# MCU_R5FSS0_CORE0_ECC_AGGR_CORE0_ECC_AGGR register map
Vendor: Texas Instruments
Peripheral module from a debugger description file (folder J721S2).
Registers are 32-bit, access not given, reset 0x0 unless marked. A register's access mark holds for its fields unless they carry their own. Offsets are as the file gives them; lines under a group give offsets from that group; [hi:lo] are bit positions; {n}, {i} and the like mark numbered series; 'fields as' and 'values as' point back to an identical list; <NAME> marks a mode.

## MCU_R5FSS0_CORE0_ECC_AGGR_CORE0_ECC_AGGR
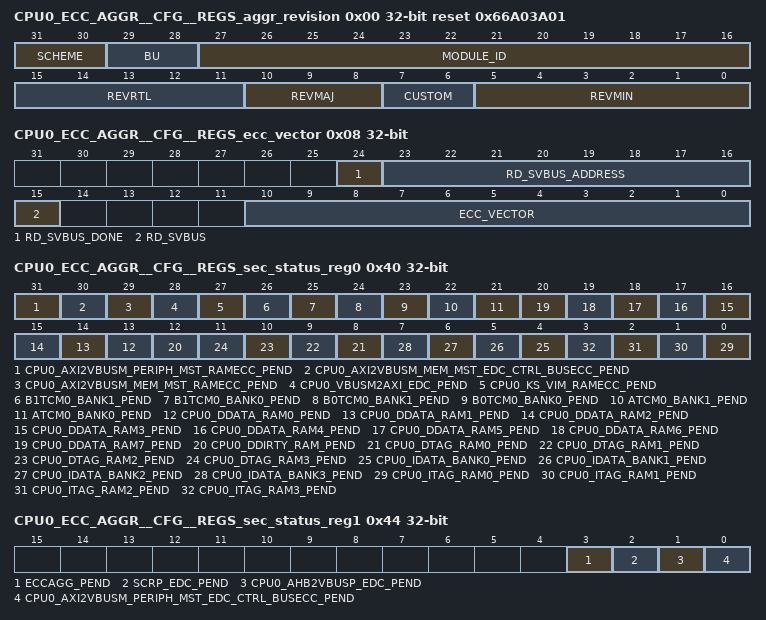
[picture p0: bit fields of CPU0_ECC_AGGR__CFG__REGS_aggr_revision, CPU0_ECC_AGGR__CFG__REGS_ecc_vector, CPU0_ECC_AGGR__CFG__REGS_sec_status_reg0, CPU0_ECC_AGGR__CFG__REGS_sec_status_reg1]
0x00 CPU0_ECC_AGGR__CFG__REGS_aggr_revision ro reset 0x66A03A01 — Revision parameters
  [31:30] SCHEME
  [29:28] BU
  [27:16] MODULE_ID
  [15:11] REVRTL — RTL version
  [10:8] REVMAJ — Major version
  [7:6] CUSTOM — Custom version
  [5:0] REVMIN — Minor version
0x08 CPU0_ECC_AGGR__CFG__REGS_ecc_vector — ECC Vector Register
  [24] RD_SVBUS_DONE — Status to indicate if read on serial VBUS is complete, write of any value will clear this bit. (access R/W1TC)
  [23:16] RD_SVBUS_ADDRESS rw — Read address
  [15] RD_SVBUS — Write 1 to trigger a read on the serial VBUS (access R/W1TS)
  [10:0] ECC_VECTOR rw — Value written to select the corresponding ECC RAM for control or status
0x0C CPU0_ECC_AGGR__CFG__REGS_misc_status ro reset 0x24 — Misc Status
  [10:0] NUM_RAMS — Indicates the number of RAMS serviced by the ECC aggregator
0x10 CPU0_ECC_AGGR__CFG__REGS_reserved_svbus rw — Reference other documents that contain the ECC RAM wrapper and EDC controller serial vbus register sets.
  [31:0] DATA — Serial VBUS register data
0x3C CPU0_ECC_AGGR__CFG__REGS_sec_eoi_reg — EOI Register
  [0] EOI_WR — EOI Register (access R/W1TS)
0x40 CPU0_ECC_AGGR__CFG__REGS_sec_status_reg0 — Interrupt Status Register 0
  [31] CPU0_AXI2VBUSM_PERIPH_MST_RAMECC_PEND — Interrupt Pending Status for cpu0_axi2vbusm_periph_mst_ramecc_pend (access R/W1TS)
  [30] CPU0_AXI2VBUSM_MEM_MST_EDC_CTRL_BUSECC_PEND — Interrupt Pending Status for cpu0_axi2vbusm_mem_mst_edc_ctrl_busecc_pend (access R/W1TS)
  [29] CPU0_AXI2VBUSM_MEM_MST_RAMECC_PEND — Interrupt Pending Status for cpu0_axi2vbusm_mem_mst_ramecc_pend (access R/W1TS)
  [28] CPU0_VBUSM2AXI_EDC_PEND — Interrupt Pending Status for cpu0_vbusm2axi_edc_pend (access R/W1TS)
  [27] CPU0_KS_VIM_RAMECC_PEND — Interrupt Pending Status for cpu0_ks_vim_ramecc_pend (access R/W1TS)
  [26] B1TCM0_BANK1_PEND — Interrupt Pending Status for b1tcm0_bank1_pend (access R/W1TS)
  [25] B1TCM0_BANK0_PEND — Interrupt Pending Status for b1tcm0_bank0_pend (access R/W1TS)
  [24] B0TCM0_BANK1_PEND — Interrupt Pending Status for b0tcm0_bank1_pend (access R/W1TS)
  [23] B0TCM0_BANK0_PEND — Interrupt Pending Status for b0tcm0_bank0_pend (access R/W1TS)
  [22] ATCM0_BANK1_PEND — Interrupt Pending Status for atcm0_bank1_pend (access R/W1TS)
  [21] ATCM0_BANK0_PEND — Interrupt Pending Status for atcm0_bank0_pend (access R/W1TS)
  [n+13] CPU0_DDATA_RAM{n}_PEND (n=0..7) — Interrupt Pending Status for cpu0_ddata_ram{n}_pend (access R/W1TS)
  [12] CPU0_DDIRTY_RAM_PEND — Interrupt Pending Status for cpu0_ddirty_ram_pend (access R/W1TS)
  [n+8] CPU0_DTAG_RAM{n}_PEND (n=0..3) — Interrupt Pending Status for cpu0_dtag_ram{n}_pend (access R/W1TS)
  [n+4] CPU0_IDATA_BANK{n}_PEND (n=0..3) — Interrupt Pending Status for cpu0_idata_bank{n}_pend (access R/W1TS)
  [n] CPU0_ITAG_RAM{n}_PEND (n=0..3) — Interrupt Pending Status for cpu0_itag_ram{n}_pend (access R/W1TS)
0x44 CPU0_ECC_AGGR__CFG__REGS_sec_status_reg1 — Interrupt Status Register 1
  [3] ECCAGG_PEND — Interrupt Pending Status for eccagg_pend (access R/W1TS)
  [2] SCRP_EDC_PEND — Interrupt Pending Status for scrp_edc_pend (access R/W1TS)
  [1] CPU0_AHB2VBUSP_EDC_PEND — Interrupt Pending Status for cpu0_ahb2vbusp_edc_pend (access R/W1TS)
  [0] CPU0_AXI2VBUSM_PERIPH_MST_EDC_CTRL_BUSECC_PEND — Interrupt Pending Status for cpu0_axi2vbusm_periph_mst_edc_ctrl_busecc_pend (access R/W1TS)
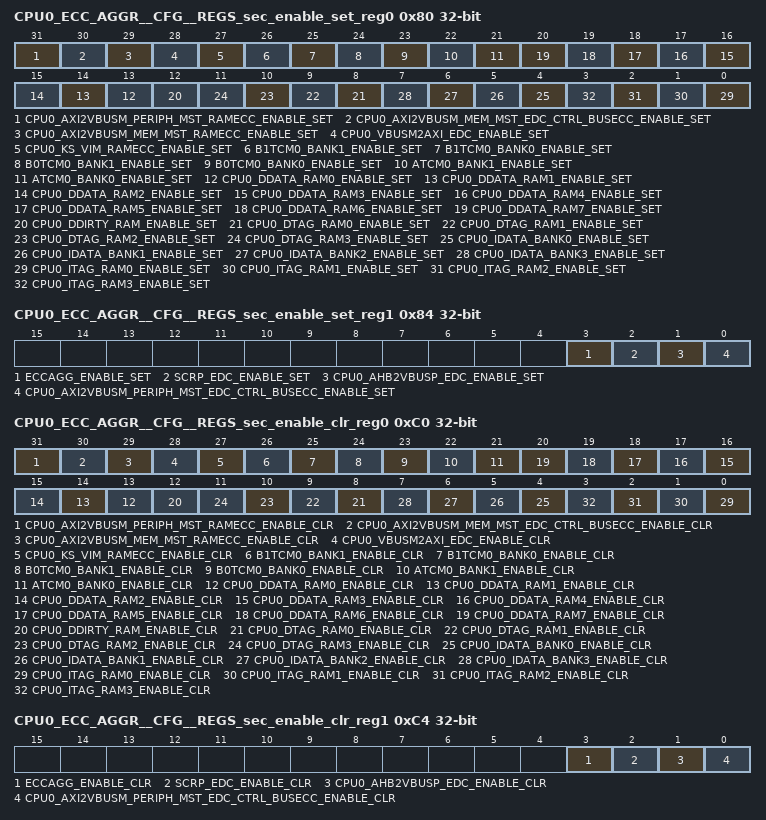
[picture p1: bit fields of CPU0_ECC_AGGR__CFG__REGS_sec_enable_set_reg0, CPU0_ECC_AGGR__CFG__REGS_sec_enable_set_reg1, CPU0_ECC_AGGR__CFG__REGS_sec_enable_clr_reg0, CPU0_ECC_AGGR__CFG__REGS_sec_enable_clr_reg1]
0x80 CPU0_ECC_AGGR__CFG__REGS_sec_enable_set_reg0 — Interrupt Enable Set Register 0
  [31] CPU0_AXI2VBUSM_PERIPH_MST_RAMECC_ENABLE_SET — Interrupt Enable Set Register for cpu0_axi2vbusm_periph_mst_ramecc_pend (access R/W1TS)
  [30] CPU0_AXI2VBUSM_MEM_MST_EDC_CTRL_BUSECC_ENABLE_SET — Interrupt Enable Set Register for cpu0_axi2vbusm_mem_mst_edc_ctrl_busecc_pend (access R/W1TS)
  [29] CPU0_AXI2VBUSM_MEM_MST_RAMECC_ENABLE_SET — Interrupt Enable Set Register for cpu0_axi2vbusm_mem_mst_ramecc_pend (access R/W1TS)
  [28] CPU0_VBUSM2AXI_EDC_ENABLE_SET — Interrupt Enable Set Register for cpu0_vbusm2axi_edc_pend (access R/W1TS)
  [27] CPU0_KS_VIM_RAMECC_ENABLE_SET — Interrupt Enable Set Register for cpu0_ks_vim_ramecc_pend (access R/W1TS)
  [26] B1TCM0_BANK1_ENABLE_SET — Interrupt Enable Set Register for b1tcm0_bank1_pend (access R/W1TS)
  [25] B1TCM0_BANK0_ENABLE_SET — Interrupt Enable Set Register for b1tcm0_bank0_pend (access R/W1TS)
  [24] B0TCM0_BANK1_ENABLE_SET — Interrupt Enable Set Register for b0tcm0_bank1_pend (access R/W1TS)
  [23] B0TCM0_BANK0_ENABLE_SET — Interrupt Enable Set Register for b0tcm0_bank0_pend (access R/W1TS)
  [22] ATCM0_BANK1_ENABLE_SET — Interrupt Enable Set Register for atcm0_bank1_pend (access R/W1TS)
  [21] ATCM0_BANK0_ENABLE_SET — Interrupt Enable Set Register for atcm0_bank0_pend (access R/W1TS)
  [n+13] CPU0_DDATA_RAM{n}_ENABLE_SET (n=0..7) — Interrupt Enable Set Register for cpu0_ddata_ram{n}_pend (access R/W1TS)
  [12] CPU0_DDIRTY_RAM_ENABLE_SET — Interrupt Enable Set Register for cpu0_ddirty_ram_pend (access R/W1TS)
  [n+8] CPU0_DTAG_RAM{n}_ENABLE_SET (n=0..3) — Interrupt Enable Set Register for cpu0_dtag_ram{n}_pend (access R/W1TS)
  [n+4] CPU0_IDATA_BANK{n}_ENABLE_SET (n=0..3) — Interrupt Enable Set Register for cpu0_idata_bank{n}_pend (access R/W1TS)
  [n] CPU0_ITAG_RAM{n}_ENABLE_SET (n=0..3) — Interrupt Enable Set Register for cpu0_itag_ram{n}_pend (access R/W1TS)
0x84 CPU0_ECC_AGGR__CFG__REGS_sec_enable_set_reg1 — Interrupt Enable Set Register 1
  [3] ECCAGG_ENABLE_SET — Interrupt Enable Set Register for eccagg_pend (access R/W1TS)
  [2] SCRP_EDC_ENABLE_SET — Interrupt Enable Set Register for scrp_edc_pend (access R/W1TS)
  [1] CPU0_AHB2VBUSP_EDC_ENABLE_SET — Interrupt Enable Set Register for cpu0_ahb2vbusp_edc_pend (access R/W1TS)
  [0] CPU0_AXI2VBUSM_PERIPH_MST_EDC_CTRL_BUSECC_ENABLE_SET — Interrupt Enable Set Register for cpu0_axi2vbusm_periph_mst_edc_ctrl_busecc_pend (access R/W1TS)
0xC0 CPU0_ECC_AGGR__CFG__REGS_sec_enable_clr_reg0 — Interrupt Enable Clear Register 0
  [31] CPU0_AXI2VBUSM_PERIPH_MST_RAMECC_ENABLE_CLR — Interrupt Enable Clear Register for cpu0_axi2vbusm_periph_mst_ramecc_pend (access R/W1TC)
  [30] CPU0_AXI2VBUSM_MEM_MST_EDC_CTRL_BUSECC_ENABLE_CLR — Interrupt Enable Clear Register for cpu0_axi2vbusm_mem_mst_edc_ctrl_busecc_pend (access R/W1TC)
  [29] CPU0_AXI2VBUSM_MEM_MST_RAMECC_ENABLE_CLR — Interrupt Enable Clear Register for cpu0_axi2vbusm_mem_mst_ramecc_pend (access R/W1TC)
  [28] CPU0_VBUSM2AXI_EDC_ENABLE_CLR — Interrupt Enable Clear Register for cpu0_vbusm2axi_edc_pend (access R/W1TC)
  [27] CPU0_KS_VIM_RAMECC_ENABLE_CLR — Interrupt Enable Clear Register for cpu0_ks_vim_ramecc_pend (access R/W1TC)
  [26] B1TCM0_BANK1_ENABLE_CLR — Interrupt Enable Clear Register for b1tcm0_bank1_pend (access R/W1TC)
  [25] B1TCM0_BANK0_ENABLE_CLR — Interrupt Enable Clear Register for b1tcm0_bank0_pend (access R/W1TC)
  [24] B0TCM0_BANK1_ENABLE_CLR — Interrupt Enable Clear Register for b0tcm0_bank1_pend (access R/W1TC)
  [23] B0TCM0_BANK0_ENABLE_CLR — Interrupt Enable Clear Register for b0tcm0_bank0_pend (access R/W1TC)
  [22] ATCM0_BANK1_ENABLE_CLR — Interrupt Enable Clear Register for atcm0_bank1_pend (access R/W1TC)
  [21] ATCM0_BANK0_ENABLE_CLR — Interrupt Enable Clear Register for atcm0_bank0_pend (access R/W1TC)
  [n+13] CPU0_DDATA_RAM{n}_ENABLE_CLR (n=0..7) — Interrupt Enable Clear Register for cpu0_ddata_ram{n}_pend (access R/W1TC)
  [12] CPU0_DDIRTY_RAM_ENABLE_CLR — Interrupt Enable Clear Register for cpu0_ddirty_ram_pend (access R/W1TC)
  [n+8] CPU0_DTAG_RAM{n}_ENABLE_CLR (n=0..3) — Interrupt Enable Clear Register for cpu0_dtag_ram{n}_pend (access R/W1TC)
  [n+4] CPU0_IDATA_BANK{n}_ENABLE_CLR (n=0..3) — Interrupt Enable Clear Register for cpu0_idata_bank{n}_pend (access R/W1TC)
  [n] CPU0_ITAG_RAM{n}_ENABLE_CLR (n=0..3) — Interrupt Enable Clear Register for cpu0_itag_ram{n}_pend (access R/W1TC)
0xC4 CPU0_ECC_AGGR__CFG__REGS_sec_enable_clr_reg1 — Interrupt Enable Clear Register 1
  [3] ECCAGG_ENABLE_CLR — Interrupt Enable Clear Register for eccagg_pend (access R/W1TC)
  [2] SCRP_EDC_ENABLE_CLR — Interrupt Enable Clear Register for scrp_edc_pend (access R/W1TC)
  [1] CPU0_AHB2VBUSP_EDC_ENABLE_CLR — Interrupt Enable Clear Register for cpu0_ahb2vbusp_edc_pend (access R/W1TC)
  [0] CPU0_AXI2VBUSM_PERIPH_MST_EDC_CTRL_BUSECC_ENABLE_CLR — Interrupt Enable Clear Register for cpu0_axi2vbusm_periph_mst_edc_ctrl_busecc_pend (access R/W1TC)
0x13C CPU0_ECC_AGGR__CFG__REGS_ded_eoi_reg — EOI Register
  [0] EOI_WR — EOI Register (access R/W1TS)
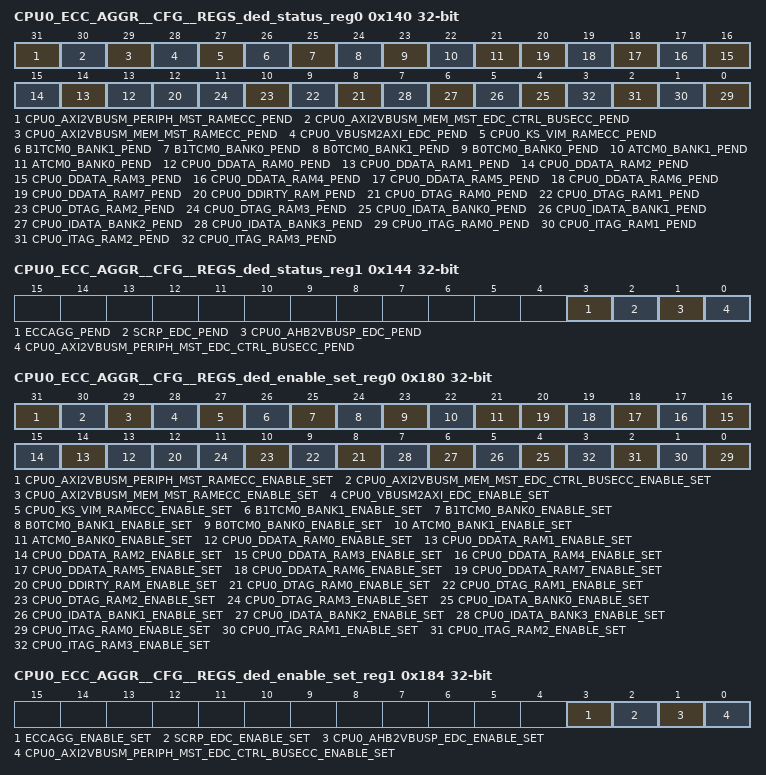
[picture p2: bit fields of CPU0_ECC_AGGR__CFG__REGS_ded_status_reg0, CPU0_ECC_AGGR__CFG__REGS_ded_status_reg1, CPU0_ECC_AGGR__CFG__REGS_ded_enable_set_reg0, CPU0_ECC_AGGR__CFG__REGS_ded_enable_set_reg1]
0x140 CPU0_ECC_AGGR__CFG__REGS_ded_status_reg0 — Interrupt Status Register 0
  fields as CPU0_ECC_AGGR__CFG__REGS_sec_status_reg0
0x144 CPU0_ECC_AGGR__CFG__REGS_ded_status_reg1 — Interrupt Status Register 1
  fields as CPU0_ECC_AGGR__CFG__REGS_sec_status_reg1
0x180 CPU0_ECC_AGGR__CFG__REGS_ded_enable_set_reg0 — Interrupt Enable Set Register 0
  fields as CPU0_ECC_AGGR__CFG__REGS_sec_enable_set_reg0
0x184 CPU0_ECC_AGGR__CFG__REGS_ded_enable_set_reg1 — Interrupt Enable Set Register 1
  fields as CPU0_ECC_AGGR__CFG__REGS_sec_enable_set_reg1
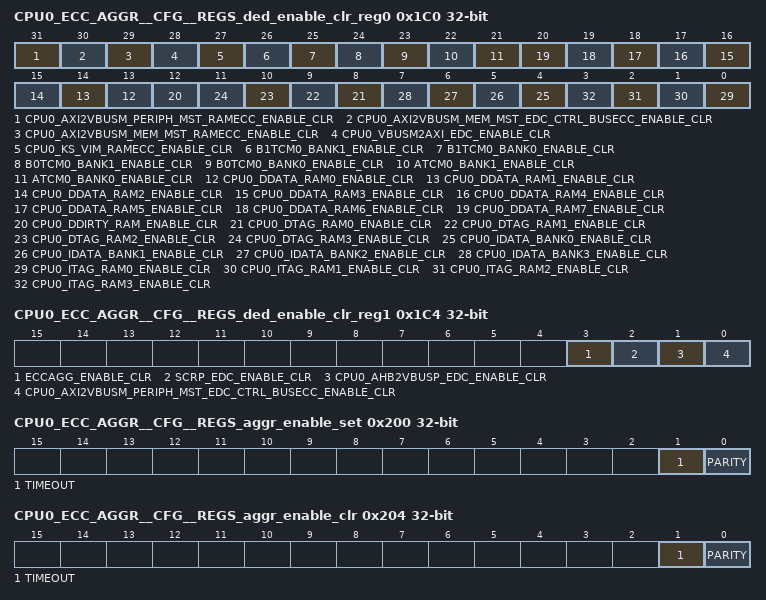
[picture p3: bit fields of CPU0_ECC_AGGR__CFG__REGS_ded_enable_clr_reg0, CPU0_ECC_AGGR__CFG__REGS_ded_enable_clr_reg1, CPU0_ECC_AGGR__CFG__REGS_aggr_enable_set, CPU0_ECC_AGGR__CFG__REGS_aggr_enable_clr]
0x1C0 CPU0_ECC_AGGR__CFG__REGS_ded_enable_clr_reg0 — Interrupt Enable Clear Register 0
  fields as CPU0_ECC_AGGR__CFG__REGS_sec_enable_clr_reg0
0x1C4 CPU0_ECC_AGGR__CFG__REGS_ded_enable_clr_reg1 — Interrupt Enable Clear Register 1
  fields as CPU0_ECC_AGGR__CFG__REGS_sec_enable_clr_reg1
0x200 CPU0_ECC_AGGR__CFG__REGS_aggr_enable_set — AGGR interrupt enable set Register
  [1] TIMEOUT — interrupt enable set for svbus timeout errors (access R/W1TS)
  [0] PARITY — interrupt enable set for parity errors (access R/W1TS)
0x204 CPU0_ECC_AGGR__CFG__REGS_aggr_enable_clr — AGGR interrupt enable clear Register
  [1] TIMEOUT — interrupt enable clear for svbus timeout errors (access R/W1TC)
  [0] PARITY — interrupt enable clear for parity errors (access R/W1TC)
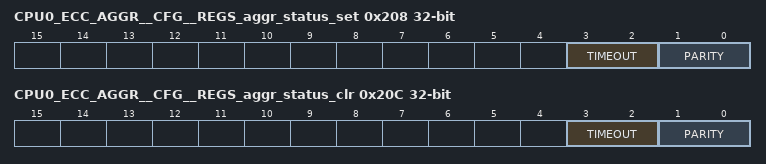
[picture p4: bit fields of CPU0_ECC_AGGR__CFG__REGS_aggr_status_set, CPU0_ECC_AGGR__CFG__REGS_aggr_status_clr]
0x208 CPU0_ECC_AGGR__CFG__REGS_aggr_status_set — AGGR interrupt status set Register
  [3:2] TIMEOUT — interrupt status set for svbus timeout errors (access R/WI)
  [1:0] PARITY — interrupt status set for parity errors (access R/WI)
0x20C CPU0_ECC_AGGR__CFG__REGS_aggr_status_clr — AGGR interrupt status clear Register
  [3:2] TIMEOUT — interrupt status clear for svbus timeout errors (access R/WD)
  [1:0] PARITY — interrupt status clear for parity errors (access R/WD)
